# PIC32MX450F128H register map
Vendor: Microchip
Registers are 32-bit, read-write, reset 0x0 unless marked. A register's access mark holds for its fields unless they carry their own. Addresses are absolute, and some are shared; only a register's first bit layout is shown; [hi:lo] are bit positions.

## ICAP1
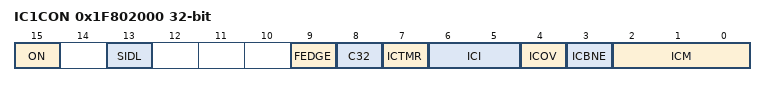
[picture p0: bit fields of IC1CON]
0x1F802000 IC1CON
  [15] ON, [13] SIDL, [9] FEDGE, [8] C32, [7] ICTMR, [6:5] ICI, [4] ICOV ro, [3] ICBNE ro, [2:0] ICM
0x1F802010 IC1BUF ro reset not defined — (power-on value xxxxxxxxxxxxxxxxxxxxxxxxxxxxxxxx)

## ICAP2
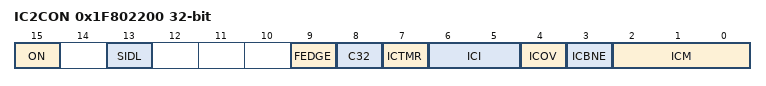
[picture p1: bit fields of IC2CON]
0x1F802200 IC2CON
  [15] ON, [13] SIDL, [9] FEDGE, [8] C32, [7] ICTMR, [6:5] ICI, [4] ICOV ro, [3] ICBNE ro, [2:0] ICM
0x1F802210 IC2BUF ro reset not defined — (power-on value xxxxxxxxxxxxxxxxxxxxxxxxxxxxxxxx)

## ICAP3
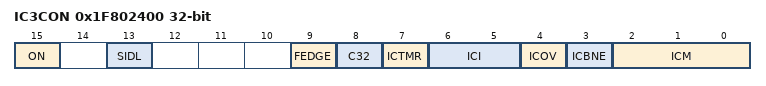
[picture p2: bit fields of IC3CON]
0x1F802400 IC3CON
  [15] ON, [13] SIDL, [9] FEDGE, [8] C32, [7] ICTMR, [6:5] ICI, [4] ICOV ro, [3] ICBNE ro, [2:0] ICM
0x1F802410 IC3BUF ro reset not defined — (power-on value xxxxxxxxxxxxxxxxxxxxxxxxxxxxxxxx)

## ICAP4
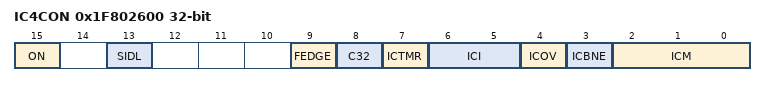
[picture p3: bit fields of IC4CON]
0x1F802600 IC4CON
  [15] ON, [13] SIDL, [9] FEDGE, [8] C32, [7] ICTMR, [6:5] ICI, [4] ICOV ro, [3] ICBNE ro, [2:0] ICM
0x1F802610 IC4BUF ro reset not defined — (power-on value xxxxxxxxxxxxxxxxxxxxxxxxxxxxxxxx)

## ICAP5
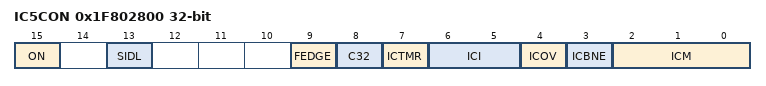
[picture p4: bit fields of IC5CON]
0x1F802800 IC5CON
  [15] ON, [13] SIDL, [9] FEDGE, [8] C32, [7] ICTMR, [6:5] ICI, [4] ICOV ro, [3] ICBNE ro, [2:0] ICM
0x1F802810 IC5BUF ro reset not defined — (power-on value xxxxxxxxxxxxxxxxxxxxxxxxxxxxxxxx)

## OCMP1
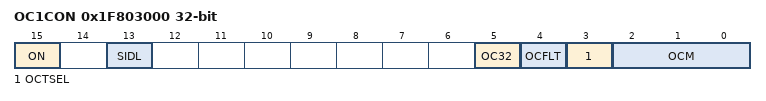
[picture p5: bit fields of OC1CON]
0x1F803000 OC1CON
  [15] ON, [13] SIDL, [5] OC32, [4] OCFLT ro, [3] OCTSEL, [2:0] OCM
0x1F803010 OC1R reset not defined — (power-on value xxxxxxxxxxxxxxxxxxxxxxxxxxxxxxxx)
0x1F803020 OC1RS reset not defined — (power-on value xxxxxxxxxxxxxxxxxxxxxxxxxxxxxxxx)

## OCMP2
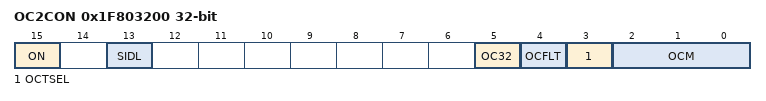
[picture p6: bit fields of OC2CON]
0x1F803200 OC2CON
  [15] ON, [13] SIDL, [5] OC32, [4] OCFLT ro, [3] OCTSEL, [2:0] OCM
0x1F803210 OC2R reset not defined — (power-on value xxxxxxxxxxxxxxxxxxxxxxxxxxxxxxxx)
0x1F803220 OC2RS reset not defined — (power-on value xxxxxxxxxxxxxxxxxxxxxxxxxxxxxxxx)

## OCMP3
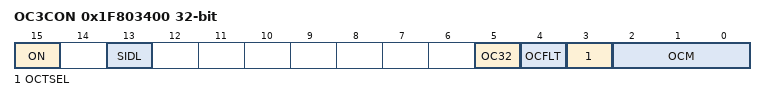
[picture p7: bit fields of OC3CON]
0x1F803400 OC3CON
  [15] ON, [13] SIDL, [5] OC32, [4] OCFLT ro, [3] OCTSEL, [2:0] OCM
0x1F803410 OC3R reset not defined — (power-on value xxxxxxxxxxxxxxxxxxxxxxxxxxxxxxxx)
0x1F803420 OC3RS reset not defined — (power-on value xxxxxxxxxxxxxxxxxxxxxxxxxxxxxxxx)

## OCMP4
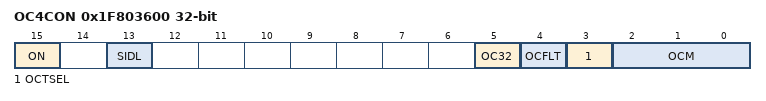
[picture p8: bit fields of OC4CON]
0x1F803600 OC4CON
  [15] ON, [13] SIDL, [5] OC32, [4] OCFLT ro, [3] OCTSEL, [2:0] OCM
0x1F803610 OC4R reset not defined — (power-on value xxxxxxxxxxxxxxxxxxxxxxxxxxxxxxxx)
0x1F803620 OC4RS reset not defined — (power-on value xxxxxxxxxxxxxxxxxxxxxxxxxxxxxxxx)

## OCMP5
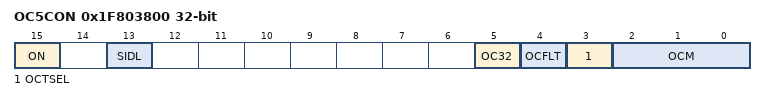
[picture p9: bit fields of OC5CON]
0x1F803800 OC5CON
  [15] ON, [13] SIDL, [5] OC32, [4] OCFLT ro, [3] OCTSEL, [2:0] OCM
0x1F803810 OC5R reset not defined — (power-on value xxxxxxxxxxxxxxxxxxxxxxxxxxxxxxxx)
0x1F803820 OC5RS reset not defined — (power-on value xxxxxxxxxxxxxxxxxxxxxxxxxxxxxxxx)

## I2C1
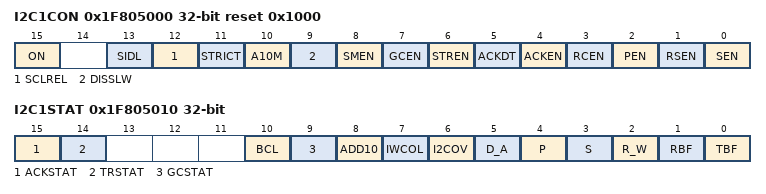
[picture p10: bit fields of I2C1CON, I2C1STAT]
0x1F805000 I2C1CON reset 0x1000
  [15] ON, [13] SIDL, [12] SCLREL, [11] STRICT, [10] A10M, [9] DISSLW, [8] SMEN, [7] GCEN, [6] STREN, [5] ACKDT, [4] ACKEN, [3] RCEN, [2] PEN, [1] RSEN, [0] SEN
0x1F805010 I2C1STAT
  [15] ACKSTAT ro
  [14] TRSTAT ro
  [10] BCL — (can only be cleared)
  [9] GCSTAT ro
  [8] ADD10 ro
  [7] IWCOL — (can only be cleared)
  [6] I2COV — (can only be cleared)
  [5] D_A ro
  [4] P — (can only be cleared)
  [3] S — (can only be cleared)
  [2] R_W ro
  [1] RBF ro
  [0] TBF ro
0x1F805020 I2C1ADD
  [9:0] I2CADD
0x1F805030 I2C1MSK
  [9:0] I2CMSK
0x1F805040 I2C1BRG
  [11:0] I2CBRG
0x1F805050 I2C1TRN
  [7:0] I2CTRN
0x1F805060 I2C1RCV
  [7:0] I2CRCV

## I2C2
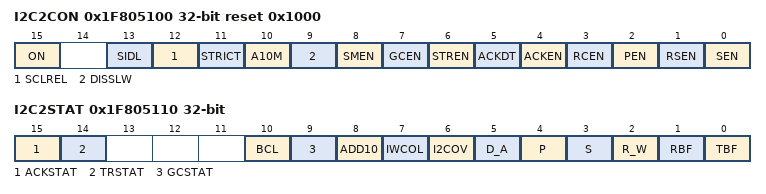
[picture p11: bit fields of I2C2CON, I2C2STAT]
0x1F805100 I2C2CON reset 0x1000
  [15] ON, [13] SIDL, [12] SCLREL, [11] STRICT, [10] A10M, [9] DISSLW, [8] SMEN, [7] GCEN, [6] STREN, [5] ACKDT, [4] ACKEN, [3] RCEN, [2] PEN, [1] RSEN, [0] SEN
0x1F805110 I2C2STAT
  [15] ACKSTAT ro
  [14] TRSTAT ro
  [10] BCL — (can only be cleared)
  [9] GCSTAT ro
  [8] ADD10 ro
  [7] IWCOL — (can only be cleared)
  [6] I2COV — (can only be cleared)
  [5] D_A ro
  [4] P — (can only be cleared)
  [3] S — (can only be cleared)
  [2] R_W ro
  [1] RBF ro
  [0] TBF ro
0x1F805120 I2C2ADD
  [9:0] I2CADD
0x1F805130 I2C2MSK
  [9:0] I2CMSK
0x1F805140 I2C2BRG
  [11:0] I2CBRG
0x1F805150 I2C2TRN
  [7:0] I2CTRN
0x1F805160 I2C2RCV
  [7:0] I2CRCV
